VERSION ""

NS_ :

BS_:

BU_: GPS

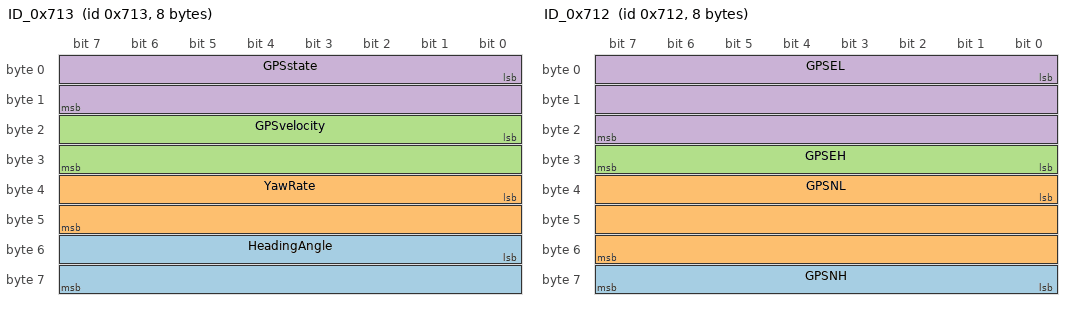
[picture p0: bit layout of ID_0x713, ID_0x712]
BO_ 1811 ID_0x713: 8 Vector__XXX
 SG_ HeadingAngle : 48|16@1- (0.01,0) [-327.68|327.67] "degree"  GPS
 SG_ YawRate : 32|16@1- (0.01,0) [-327.68|327.67] "degree"  GPS
 SG_ GPSvelocity : 16|16@1+ (0.01,0) [0|655.35] ""  GPS
 SG_ GPSstate : 0|16@1+ (1,0) [0|65535] ""  GPS

BO_ 1810 ID_0x712: 8 Vector__XXX
 SG_ GPSNH : 56|8@1+ (1,0) [0|255] ""  GPS
 SG_ GPSNL : 32|24@1+ (1E-007,0) [0|1.6777215] ""  GPS
 SG_ GPSEH : 24|8@1+ (1,0) [0|255] ""  GPS
 SG_ GPSEL : 0|24@1+ (1E-007,0) [0|1.6777215] ""  GPS

BO_ 1808 ID_0x710: 8 Vector__XXX
 SG_ PitchAngle : 16|16@1- (0.01,0) [-327.68|327.67] "degree"  GPS
 SG_ RollAngle : 0|16@1- (0.01,0) [-327.68|327.67] ""  GPS

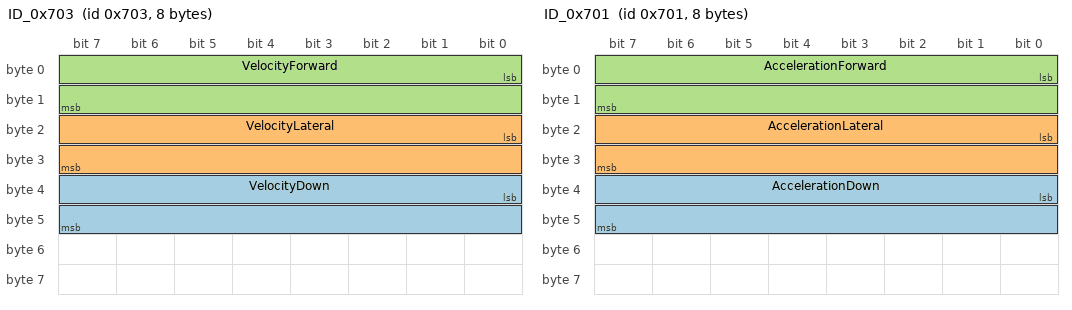
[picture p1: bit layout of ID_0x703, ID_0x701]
BO_ 1795 ID_0x703: 8 Vector__XXX
 SG_ VelocityDown : 32|16@1- (0.01,0) [-327.68|327.67] "m/s"  GPS
 SG_ VelocityLateral : 16|16@1- (0.01,0) [-327.68|327.67] "m/s"  GPS
 SG_ VelocityForward : 0|16@1- (0.01,0) [-327.68|327.67] "m/s"  GPS

BO_ 1793 ID_0x701: 8 Vector__XXX
 SG_ AccelerationDown : 32|16@1- (0.001,0) [-32.768|32.767] "m/s^2"  GPS
 SG_ AccelerationLateral : 16|16@1- (0.001,0) [-32.768|32.767] "m/s^2"  GPS
 SG_ AccelerationForward : 0|16@1- (0.001,0) [-32.768|32.767] "m/s^2"  GPS

BA_DEF_  "BusType" STRING ;
BA_DEF_DEF_  "BusType" "CAN";
